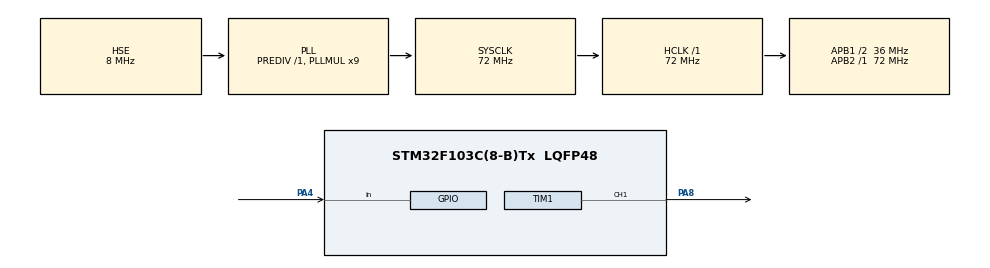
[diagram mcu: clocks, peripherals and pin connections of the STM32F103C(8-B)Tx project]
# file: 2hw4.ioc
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Mcu.Family=STM32F1
Mcu.Name=STM32F103C(8-B)Tx
Mcu.Package=LQFP48
NVIC.PriorityGroup=NVIC_PRIORITYGROUP_4
NVIC.TIM1_UP_IRQn=true\:0\:0\:false\:false\:true\:true\:true\:true
NVIC.TIM2_IRQn=true\:0\:0\:false\:false\:true\:true\:true\:true
PA13.Mode=Serial_Wire
PA13.Signal=SYS_JTMS-SWDIO
PA14.Mode=Serial_Wire
PA14.Signal=SYS_JTCK-SWCLK
PA15.Signal=S_TIM2_CH1_ETR
PA4.GPIO_PuPd=GPIO_PULLUP
PA4.Signal=GPIO_Input
PA8.Signal=S_TIM1_CH1
PD0-OSC_IN.Mode=HSE-External-Oscillator
PD0-OSC_IN.Signal=RCC_OSC_IN
PD1-OSC_OUT.Mode=HSE-External-Oscillator
PD1-OSC_OUT.Signal=RCC_OSC_OUT
ProjectManager.HeapSize=0x200
ProjectManager.StackSize=0x400
ProjectManager.TargetToolchain=CMake
RCC.AHBFreq_Value=72000000
RCC.APB1CLKDivider=RCC_HCLK_DIV2
RCC.APB1Freq_Value=36000000
RCC.APB1TimFreq_Value=72000000
RCC.APB2Freq_Value=72000000
RCC.APB2TimFreq_Value=72000000
RCC.HCLKFreq_Value=72000000
RCC.PLLMUL=RCC_PLL_MUL9
RCC.PLLSourceVirtual=RCC_PLLSOURCE_HSE
RCC.SYSCLKFreq_VALUE=72000000
RCC.SYSCLKSource=RCC_SYSCLKSOURCE_PLLCLK
RCC.USBFreq_Value=72000000
SH.S_TIM1_CH1.0=TIM1_CH1,PWM Generation1 CH1
SH.S_TIM2_CH1_ETR.0=TIM2_CH1
TIM1.AutoReloadPreload=TIM_AUTORELOAD_PRELOAD_ENABLE
TIM1.Channel-PWM\ Generation1\ CH1=TIM_CHANNEL_1
TIM1.Period=199
TIM1.Prescaler=719
TIM2.AutoReloadPreload=TIM_AUTORELOAD_PRELOAD_ENABLE
TIM2.Period=199
TIM2.Prescaler=719
VP_TIM1_VS_ClockSourceINT.Mode=Internal
VP_TIM2_VS_ClockSourceINT.Mode=Internal
board=custom

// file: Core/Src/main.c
/* USER CODE BEGIN Header */
/**
  ******************************************************************************
  * @file           : main.c
  * @brief          : Main program body
  ******************************************************************************
  * @attention
  *
  * Copyright (c) 2026 STMicroelectronics.
  * All rights reserved.
  *
  * This software is licensed under terms that can be found in the LICENSE file
  * in the root directory of this software component.
  * If no LICENSE file comes with this software, it is provided AS-IS.
  *
  ******************************************************************************
  */
/* USER CODE END Header */
#include "main.h"
#include "tim.h"
#include "gpio.h"

/* USER CODE BEGIN Includes */
#include <math.h>
/* USER CODE END Includes */

/* USER CODE BEGIN PV */
volatile uint32_t mode = 0;  //0: no mode , 1: 25% duty , 2: 50% duty , 3: 75% duty , 4: 100% duty , 5: mode change , 6: sine wave
volatile uint16_t new_state = 0;   //0: no key pressed , 1: shot key pressed , 2: long key pressed
volatile uint16_t last_state = 0;     // record the last state of the key
volatile uint16_t tim_cnt = 0;   // record the time of the callback
volatile uint16_t long_press_cnt = 0;
/* USER CODE END PV */

void SystemClock_Config(void);

int main(void)
{

  /* MCU Configuration--------------------------------------------------------*/

  /* Reset of all peripherals, Initializes the Flash interface and the Systick. */
  HAL_Init();

  /* Configure the system clock */
  SystemClock_Config();

  /* Initialize all configured peripherals */
  MX_GPIO_Init();
  MX_TIM1_Init();
  MX_TIM2_Init();
  /* USER CODE BEGIN 2 */
  HAL_TIM_PWM_Start(&htim1, TIM_CHANNEL_1);
  /* USER CODE END 2 */

  /* Infinite loop */
  while (1)
  {

    /* USER CODE BEGIN 3 */
    float duty = 0;

    if (HAL_GPIO_ReadPin(GPIOA, GPIO_PIN_4) == GPIO_PIN_RESET)
    {
      HAL_TIM_Base_Start_IT(&htim2);
    }

    if (HAL_GPIO_ReadPin(GPIOA, GPIO_PIN_4) == GPIO_PIN_SET && tim_cnt >= 500)
    {
      new_state = 2;
      tim_cnt = 0;
      mode = 6;
      long_press_cnt++;
    }
    else if (HAL_GPIO_ReadPin(GPIOA, GPIO_PIN_4) == GPIO_PIN_SET && tim_cnt < 500 && tim_cnt > 0)
    {
      new_state = 1;
      tim_cnt = 0;
      mode++;
      if (mode >= 5)
      {
        mode = 1;
      }
    }

    if (new_state == 2 && last_state == 2)
    {
      new_state = 0;
    }

    last_state = new_state;

    float t=HAL_GetTick()/1000.0f;

    if (mode == 1)
    {duty=0.25;}
    if (mode == 2)
    {duty=0.5;}
    if (mode == 3)
    {duty=0.75;}
    if (mode == 4)
    {duty=1.0;}
    if (mode == 6)
    {
      if (long_press_cnt %2 == 0)
      {
      duty = 0;
      }
      else
      {
      duty=0.5*sin(3.14*t)+0.5;
      }
    }

    uint16_t arr=__HAL_TIM_GET_AUTORELOAD(&htim1);
    uint16_t ccr=(uint16_t)(duty*(arr+1));
    __HAL_TIM_SET_COMPARE(&htim1, TIM_CHANNEL_1,ccr);

  }
  /* USER CODE END 3 */
}

void SystemClock_Config(void)
{
  RCC_OscInitTypeDef RCC_OscInitStruct = {0};
  RCC_ClkInitTypeDef RCC_ClkInitStruct = {0};

  /** Initializes the RCC Oscillators according to the specified parameters
  * in the RCC_OscInitTypeDef structure.
  */
  RCC_OscInitStruct.OscillatorType = RCC_OSCILLATORTYPE_HSE;
  RCC_OscInitStruct.HSEState = RCC_HSE_ON;
  RCC_OscInitStruct.HSEPredivValue = RCC_HSE_PREDIV_DIV1;
  RCC_OscInitStruct.HSIState = RCC_HSI_ON;
  RCC_OscInitStruct.PLL.PLLState = RCC_PLL_ON;
  RCC_OscInitStruct.PLL.PLLSource = RCC_PLLSOURCE_HSE;
  RCC_OscInitStruct.PLL.PLLMUL = RCC_PLL_MUL9;
  if (HAL_RCC_OscConfig(&RCC_OscInitStruct) != HAL_OK)
  {
    Error_Handler();
  }

  /** Initializes the CPU, AHB and APB buses clocks
  */
  RCC_ClkInitStruct.ClockType = RCC_CLOCKTYPE_HCLK|RCC_CLOCKTYPE_SYSCLK
                              |RCC_CLOCKTYPE_PCLK1|RCC_CLOCKTYPE_PCLK2;
  RCC_ClkInitStruct.SYSCLKSource = RCC_SYSCLKSOURCE_PLLCLK;
  RCC_ClkInitStruct.AHBCLKDivider = RCC_SYSCLK_DIV1;
  RCC_ClkInitStruct.APB1CLKDivider = RCC_HCLK_DIV2;
  RCC_ClkInitStruct.APB2CLKDivider = RCC_HCLK_DIV1;

  if (HAL_RCC_ClockConfig(&RCC_ClkInitStruct, FLASH_LATENCY_2) != HAL_OK)
  {
    Error_Handler();
  }
}

/* USER CODE BEGIN 4 */
void HAL_TIM_PeriodElapsedCallback(TIM_HandleTypeDef *htim)
{
  if (htim->Instance == TIM2)
  {
    tim_cnt ++;
    HAL_TIM_Base_Stop_IT(&htim2);
  }
}
/* USER CODE END 4 */

void Error_Handler(void)
{
  __disable_irq();
  while (1)
  {
  }
}
